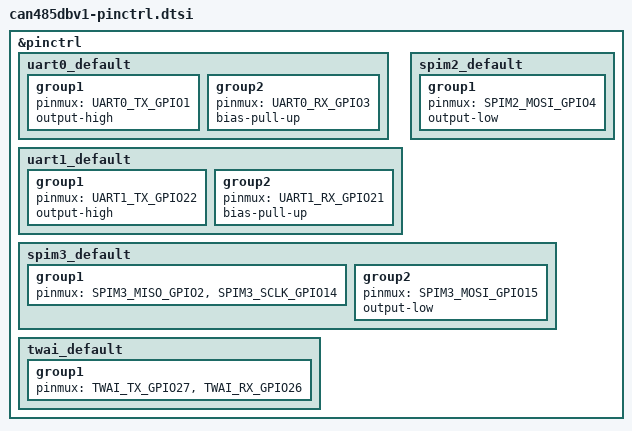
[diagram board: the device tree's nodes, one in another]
/*
 * SPDX-FileCopyrightText: Copyright (c) 2022 Espressif Systems (Shanghai) Co., Ltd.
 * SPDX-FileCopyrightText: Copyright (c) 2026 Navimatix GmbH
 * SPDX-FileCopyrightText: Copyright (c) 2026 TiaC Systems
 * SPDX-License-Identifier: Apache-2.0
 */

#include <zephyr/dt-bindings/pinctrl/esp-pinctrl-common.h>
#include <zephyr/dt-bindings/pinctrl/esp32-pinctrl.h>
#include <zephyr/dt-bindings/pinctrl/esp32-gpio-sigmap.h>

&pinctrl {
	uart0_default: uart0_default {
		group1 {
			pinmux = <UART0_TX_GPIO1>;
			output-high;
		};

		group2 {
			pinmux = <UART0_RX_GPIO3>;
			bias-pull-up;
		};
	};

	uart1_default: uart1_default {
		group1 {
			pinmux = <UART1_TX_GPIO22>; /* RS485_DI */
			output-high;
		};

		group2 {
			pinmux = <UART1_RX_GPIO21>; /* RS485_RO */
			bias-pull-up;
		};
	};

	spim2_default: spim2_default {
		group1 {
			pinmux = <SPIM2_MOSI_GPIO4>;
			output-low;
		};
	};

	spim3_default: spim3_default {
		group1 {
			pinmux = <SPIM3_MISO_GPIO2>,
				 <SPIM3_SCLK_GPIO14>;
		};

		group2 {
			pinmux = <SPIM3_MOSI_GPIO15>;
			output-low;
		};
	};

	twai_default: twai_default {
		group1 {
			pinmux = <TWAI_TX_GPIO27>,
				 <TWAI_RX_GPIO26>;
		};
	};
};
